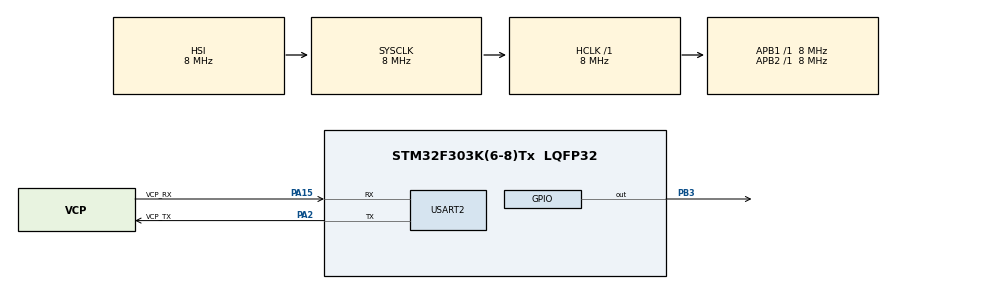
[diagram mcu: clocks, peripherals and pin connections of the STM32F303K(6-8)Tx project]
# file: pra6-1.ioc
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Mcu.Family=STM32F3
Mcu.Name=STM32F303K(6-8)Tx
Mcu.Package=LQFP32
NVIC.PriorityGroup=NVIC_PRIORITYGROUP_4
NVIC.TIM6_DAC1_IRQn=true\:0\:0\:false\:false\:true\:true\:true
PA13.GPIO_Label=SWDIO
PA13.Mode=Serial_Wire
PA13.Signal=SYS_JTMS-SWDIO
PA14.GPIO_Label=SWCLK
PA14.Mode=Serial_Wire
PA14.Signal=SYS_JTCK-SWCLK
PA15.GPIO_Label=VCP_RX
PA15.Mode=Asynchronous
PA15.Signal=USART2_RX
PA2.GPIO_Label=VCP_TX
PA2.Mode=Asynchronous
PA2.Signal=USART2_TX
PB3.Signal=GPIO_Output
PF0\ /\ OSC_IN.GPIO_Label=MCO
PF0\ /\ OSC_IN.Mode=HSE-External-Clock-Source
PF0\ /\ OSC_IN.Signal=RCC_OSC_IN
ProjectManager.HeapSize=0x200
ProjectManager.StackSize=0x400
ProjectManager.TargetToolchain=STM32CubeIDE
RCC.AHBFreq_Value=8000000
RCC.APB1Freq_Value=8000000
RCC.APB2Freq_Value=8000000
RCC.CortexFreq_Value=8000000
RCC.HSE_VALUE=8000000
RCC.HSI_VALUE=8000000
RCC.SYSCLKFreq_VALUE=8000000
TIM6.AutoReloadPreload=TIM_AUTORELOAD_PRELOAD_ENABLE
TIM6.Period=62500
TIM6.Prescaler=127
USART2.VirtualMode-Asynchronous=VM_ASYNC
VP_TIM6_VS_ClockSourceINT.Mode=Enable_Timer
board=NUCLEO-F303K8

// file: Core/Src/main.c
/* USER CODE BEGIN Header */
/**
  ******************************************************************************
  * @file           : main.c
  * @brief          : Main program body
  ******************************************************************************
  * @attention
  *
  * <h2><center>&copy; Copyright (c) 2021 STMicroelectronics.
  * All rights reserved.</center></h2>
  *
  * This software component is licensed by ST under BSD 3-Clause license,
  * the "License"; You may not use this file except in compliance with the
  * License. You may obtain a copy of the License at:
  *                        opensource.org/licenses/BSD-3-Clause
  *
  ******************************************************************************
  */
/* USER CODE END Header */
#include "main.h"

TIM_HandleTypeDef htim6;

UART_HandleTypeDef huart2;

void SystemClock_Config(void);
static void MX_GPIO_Init(void);
static void MX_USART2_UART_Init(void);
static void MX_TIM6_Init(void);

int main(void)
{

  /* MCU Configuration--------------------------------------------------------*/

  /* Reset of all peripherals, Initializes the Flash interface and the Systick. */
  HAL_Init();

  /* Configure the system clock */
  SystemClock_Config();

  /* Initialize all configured peripherals */
  MX_GPIO_Init();
  MX_USART2_UART_Init();
  MX_TIM6_Init();

  /* Infinite loop */
  /* USER CODE BEGIN WHILE */
  HAL_TIM_Base_Start_IT(&htim6);
  while (1)
  {
    /* USER CODE END WHILE */

  }
}

void SystemClock_Config(void)
{
  RCC_OscInitTypeDef RCC_OscInitStruct = {0};
  RCC_ClkInitTypeDef RCC_ClkInitStruct = {0};

  /** Initializes the RCC Oscillators according to the specified parameters
  * in the RCC_OscInitTypeDef structure.
  */
  RCC_OscInitStruct.OscillatorType = RCC_OSCILLATORTYPE_HSI;
  RCC_OscInitStruct.HSIState = RCC_HSI_ON;
  RCC_OscInitStruct.HSICalibrationValue = RCC_HSICALIBRATION_DEFAULT;
  RCC_OscInitStruct.PLL.PLLState = RCC_PLL_NONE;
  if (HAL_RCC_OscConfig(&RCC_OscInitStruct) != HAL_OK)
  {
    Error_Handler();
  }
  /** Initializes the CPU, AHB and APB buses clocks
  */
  RCC_ClkInitStruct.ClockType = RCC_CLOCKTYPE_HCLK|RCC_CLOCKTYPE_SYSCLK
                              |RCC_CLOCKTYPE_PCLK1|RCC_CLOCKTYPE_PCLK2;
  RCC_ClkInitStruct.SYSCLKSource = RCC_SYSCLKSOURCE_HSI;
  RCC_ClkInitStruct.AHBCLKDivider = RCC_SYSCLK_DIV1;
  RCC_ClkInitStruct.APB1CLKDivider = RCC_HCLK_DIV1;
  RCC_ClkInitStruct.APB2CLKDivider = RCC_HCLK_DIV1;

  if (HAL_RCC_ClockConfig(&RCC_ClkInitStruct, FLASH_LATENCY_0) != HAL_OK)
  {
    Error_Handler();
  }
}

static void MX_TIM6_Init(void)
{

  TIM_MasterConfigTypeDef sMasterConfig = {0};

  htim6.Instance = TIM6;
  htim6.Init.Prescaler = 127;
  htim6.Init.CounterMode = TIM_COUNTERMODE_UP;
  htim6.Init.Period = 62500;
  htim6.Init.AutoReloadPreload = TIM_AUTORELOAD_PRELOAD_ENABLE;
  if (HAL_TIM_Base_Init(&htim6) != HAL_OK)
  {
    Error_Handler();
  }
  sMasterConfig.MasterOutputTrigger = TIM_TRGO_RESET;
  sMasterConfig.MasterSlaveMode = TIM_MASTERSLAVEMODE_DISABLE;
  if (HAL_TIMEx_MasterConfigSynchronization(&htim6, &sMasterConfig) != HAL_OK)
  {
    Error_Handler();
  }

}

static void MX_USART2_UART_Init(void)
{

  huart2.Instance = USART2;
  huart2.Init.BaudRate = 38400;
  huart2.Init.WordLength = UART_WORDLENGTH_8B;
  huart2.Init.StopBits = UART_STOPBITS_1;
  huart2.Init.Parity = UART_PARITY_NONE;
  huart2.Init.Mode = UART_MODE_TX_RX;
  huart2.Init.HwFlowCtl = UART_HWCONTROL_NONE;
  huart2.Init.OverSampling = UART_OVERSAMPLING_16;
  huart2.Init.OneBitSampling = UART_ONE_BIT_SAMPLE_DISABLE;
  huart2.AdvancedInit.AdvFeatureInit = UART_ADVFEATURE_NO_INIT;
  if (HAL_UART_Init(&huart2) != HAL_OK)
  {
    Error_Handler();
  }

}

static void MX_GPIO_Init(void)
{
  GPIO_InitTypeDef GPIO_InitStruct = {0};

  /* GPIO Ports Clock Enable */
  __HAL_RCC_GPIOF_CLK_ENABLE();
  __HAL_RCC_GPIOA_CLK_ENABLE();
  __HAL_RCC_GPIOB_CLK_ENABLE();

  /*Configure GPIO pin Output Level */
  HAL_GPIO_WritePin(GPIOB, GPIO_PIN_3, GPIO_PIN_RESET);

  /*Configure GPIO pin : PB3 */
  GPIO_InitStruct.Pin = GPIO_PIN_3;
  GPIO_InitStruct.Mode = GPIO_MODE_OUTPUT_PP;
  GPIO_InitStruct.Pull = GPIO_NOPULL;
  GPIO_InitStruct.Speed = GPIO_SPEED_FREQ_LOW;
  HAL_GPIO_Init(GPIOB, &GPIO_InitStruct);

}

/* USER CODE BEGIN 4 */
void HAL_TIM_PeriodElapsedCallback(TIM_HandleTypeDef* htim){
	HAL_GPIO_TogglePin(GPIOB,GPIO_PIN_3);
}
/* USER CODE END 4 */

void Error_Handler(void)
{
}

/************************ (C) COPYRIGHT STMicroelectronics *****END OF FILE****/
